# ATSAMC21N18A register map
Registers are 32-bit, access not given, no defined reset value unless marked. A register's access mark holds for its fields unless they carry their own. Addresses are absolute; registers are grouped by the start of their names; [hi:lo] are bit positions; 'fields as' and 'values as' point back to an identical list.

## FUSES
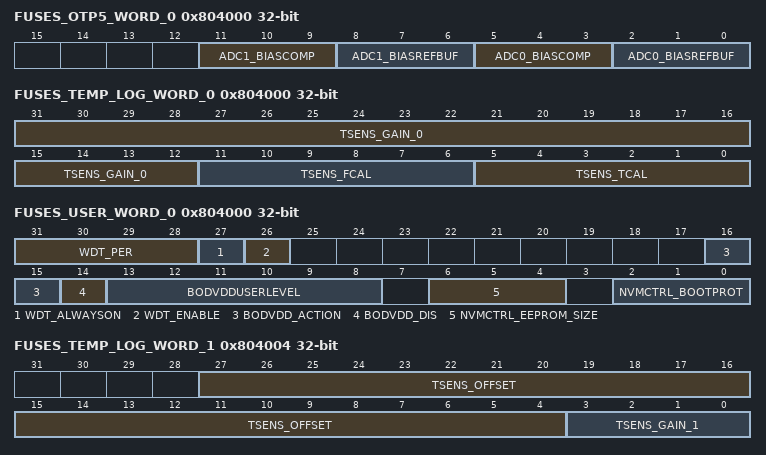
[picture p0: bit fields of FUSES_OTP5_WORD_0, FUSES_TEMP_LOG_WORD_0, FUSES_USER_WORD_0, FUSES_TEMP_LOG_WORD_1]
0x804000 FUSES_OTP5_WORD_0 — OTP5 Page Word 0
  [11:9] ADC1_BIASCOMP, [8:6] ADC1_BIASREFBUF, [5:3] ADC0_BIASCOMP, [2:0] ADC0_BIASREFBUF
0x804000 FUSES_TEMP_LOG_WORD_0 — TEMP_LOG Page Word 0
  [31:12] TSENS_GAIN_0, [11:6] TSENS_FCAL, [5:0] TSENS_TCAL
0x804000 FUSES_USER_WORD_0 — USER Page Word 0
  [31:28] WDT_PER, [27] WDT_ALWAYSON, [26] WDT_ENABLE, [16:15] BODVDD_ACTION, [14] BODVDD_DIS, [13:8] BODVDDUSERLEVEL, [6:4] NVMCTRL_EEPROM_SIZE, [2:0] NVMCTRL_BOOTPROT
0x804004 FUSES_OTP3_WORD_1 — OTP3 Page Word 1
  [31] NVMCTRL_DUMMY2
0x804004 FUSES_TEMP_LOG_WORD_1 — TEMP_LOG Page Word 1
  [27:4] TSENS_OFFSET, [3:0] TSENS_GAIN_1
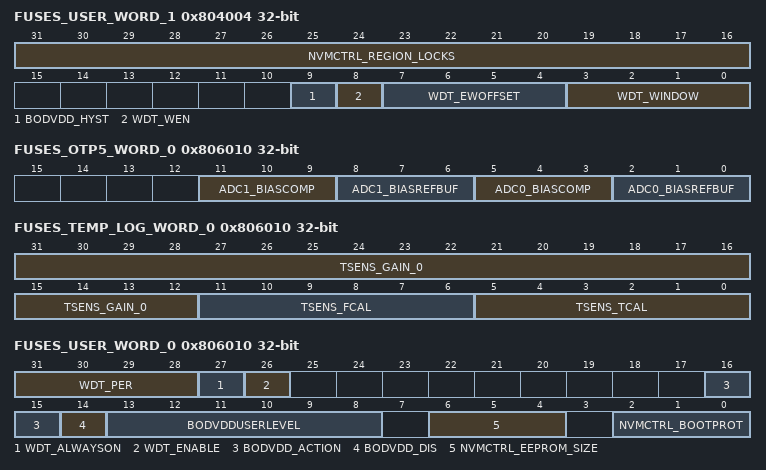
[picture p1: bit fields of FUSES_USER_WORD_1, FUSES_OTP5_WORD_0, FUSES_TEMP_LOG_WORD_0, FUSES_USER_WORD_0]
0x804004 FUSES_USER_WORD_1 — USER Page Word 1
  [31:16] NVMCTRL_REGION_LOCKS, [9] BODVDD_HYST, [8] WDT_WEN, [7:4] WDT_EWOFFSET, [3:0] WDT_WINDOW
0x806010 FUSES_OTP5_WORD_0 — OTP5 Page Word 0
  fields as FUSES_OTP5_WORD_0
0x806010 FUSES_TEMP_LOG_WORD_0 — TEMP_LOG Page Word 0
  [31:12] TSENS_GAIN_0, [11:6] TSENS_FCAL, [5:0] TSENS_TCAL
0x806010 FUSES_USER_WORD_0 — USER Page Word 0
  fields as FUSES_USER_WORD_0
0x806014 FUSES_OTP3_WORD_1 — OTP3 Page Word 1
  [31] NVMCTRL_DUMMY2
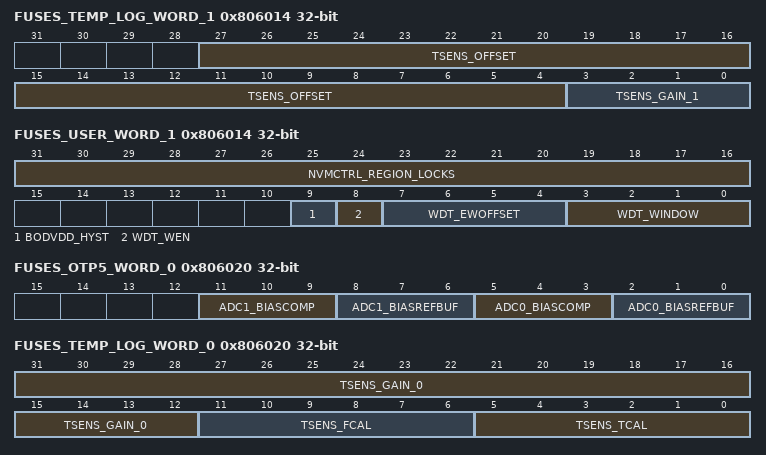
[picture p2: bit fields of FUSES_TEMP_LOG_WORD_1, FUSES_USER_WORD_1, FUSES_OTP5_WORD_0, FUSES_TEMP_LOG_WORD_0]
0x806014 FUSES_TEMP_LOG_WORD_1 — TEMP_LOG Page Word 1
  [27:4] TSENS_OFFSET, [3:0] TSENS_GAIN_1
0x806014 FUSES_USER_WORD_1 — USER Page Word 1
  fields as FUSES_USER_WORD_1
0x806020 FUSES_OTP5_WORD_0 — OTP5 Page Word 0
  fields as FUSES_OTP5_WORD_0
0x806020 FUSES_TEMP_LOG_WORD_0 — TEMP_LOG Page Word 0
  [31:12] TSENS_GAIN_0, [11:6] TSENS_FCAL, [5:0] TSENS_TCAL
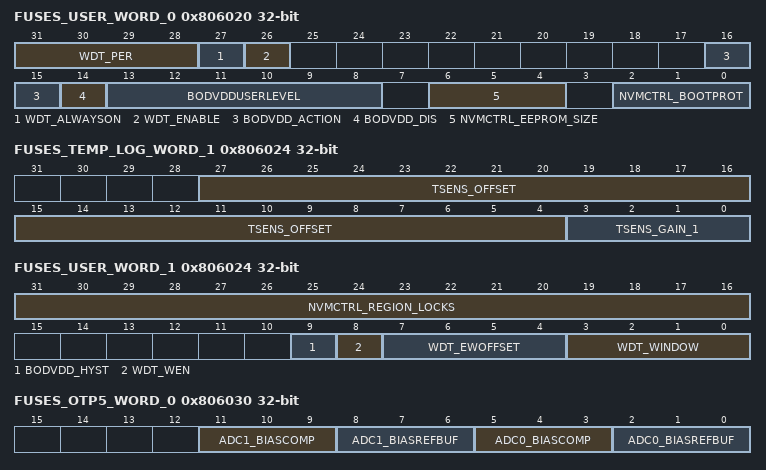
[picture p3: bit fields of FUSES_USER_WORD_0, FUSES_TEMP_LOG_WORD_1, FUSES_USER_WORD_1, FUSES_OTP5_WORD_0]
0x806020 FUSES_USER_WORD_0 — USER Page Word 0
  fields as FUSES_USER_WORD_0
0x806024 FUSES_OTP3_WORD_1 — OTP3 Page Word 1
  [31] NVMCTRL_DUMMY2
0x806024 FUSES_TEMP_LOG_WORD_1 — TEMP_LOG Page Word 1
  [27:4] TSENS_OFFSET, [3:0] TSENS_GAIN_1
0x806024 FUSES_USER_WORD_1 — USER Page Word 1
  fields as FUSES_USER_WORD_1
0x806030 FUSES_OTP5_WORD_0 — OTP5 Page Word 0
  fields as FUSES_OTP5_WORD_0
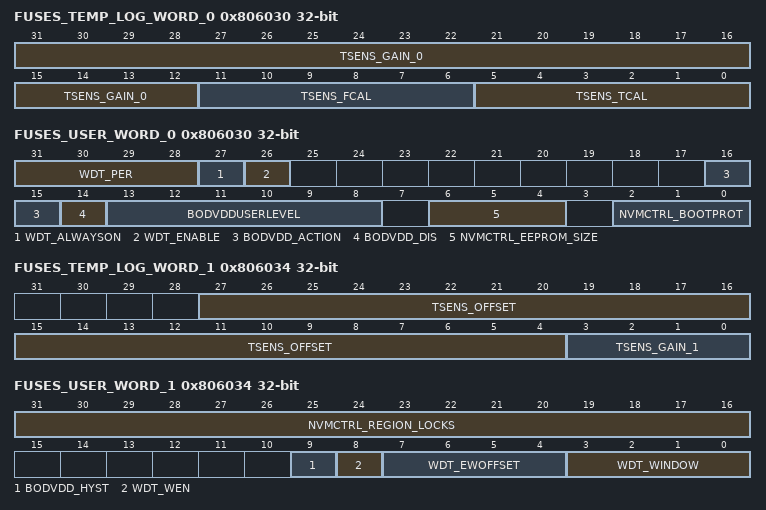
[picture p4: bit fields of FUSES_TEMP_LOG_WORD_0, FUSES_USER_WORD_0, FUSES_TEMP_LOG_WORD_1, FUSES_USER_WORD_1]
0x806030 FUSES_TEMP_LOG_WORD_0 — TEMP_LOG Page Word 0
  [31:12] TSENS_GAIN_0, [11:6] TSENS_FCAL, [5:0] TSENS_TCAL
0x806030 FUSES_USER_WORD_0 — USER Page Word 0
  fields as FUSES_USER_WORD_0
0x806034 FUSES_OTP3_WORD_1 — OTP3 Page Word 1
  [31] NVMCTRL_DUMMY2
0x806034 FUSES_TEMP_LOG_WORD_1 — TEMP_LOG Page Word 1
  [27:4] TSENS_OFFSET, [3:0] TSENS_GAIN_1
0x806034 FUSES_USER_WORD_1 — USER Page Word 1
  fields as FUSES_USER_WORD_1

## OSCCTRL
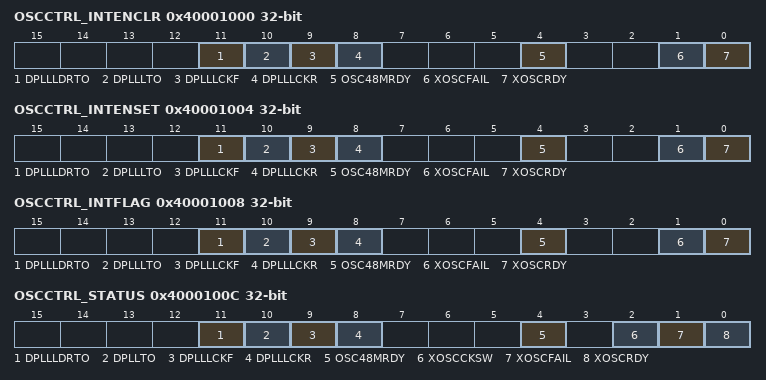
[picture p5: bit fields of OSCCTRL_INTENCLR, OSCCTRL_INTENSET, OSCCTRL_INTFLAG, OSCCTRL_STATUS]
0x40001000 OSCCTRL_INTENCLR — Interrupt Enable Clear
  [11] DPLLLDRTO, [10] DPLLLTO, [9] DPLLLCKF, [8] DPLLLCKR, [4] OSC48MRDY, [1] XOSCFAIL, [0] XOSCRDY
0x40001004 OSCCTRL_INTENSET — Interrupt Enable Set
  fields as OSCCTRL_INTENCLR
0x40001008 OSCCTRL_INTFLAG — Interrupt Flag Status and Clear
  fields as OSCCTRL_INTENCLR
0x4000100C OSCCTRL_STATUS — Power and Clocks Status
  [11] DPLLLDRTO, [10] DPLLTO, [9] DPLLLCKF, [8] DPLLLCKR, [4] OSC48MRDY, [2] XOSCCKSW, [1] XOSCFAIL, [0] XOSCRDY
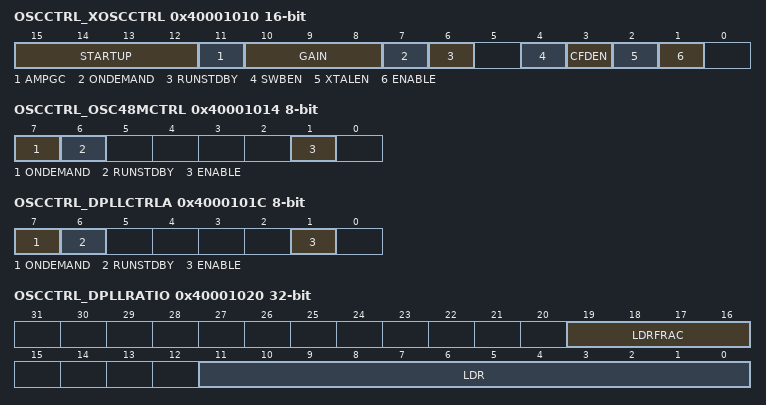
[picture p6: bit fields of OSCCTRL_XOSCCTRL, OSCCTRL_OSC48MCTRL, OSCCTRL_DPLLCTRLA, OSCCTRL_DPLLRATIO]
0x40001010 OSCCTRL_XOSCCTRL 16-bit — External Multipurpose Crystal Oscillator (XOSC) Control
  [15:12] STARTUP, [11] AMPGC, [10:8] GAIN, [7] ONDEMAND, [6] RUNSTDBY, [4] SWBEN, [3] CFDEN, [2] XTALEN, [1] ENABLE
0x40001012 OSCCTRL_CFDPRESC 8-bit — Clock Failure Detector Prescaler
  [2:0] CFDPRESC
0x40001013 OSCCTRL_EVCTRL 8-bit — Event Control
  [0] CFDEO
0x40001014 OSCCTRL_OSC48MCTRL 8-bit — 48MHz Internal Oscillator (OSC48M) Control
  [7] ONDEMAND, [6] RUNSTDBY, [1] ENABLE
0x40001015 OSCCTRL_OSC48MDIV 8-bit — OSC48M Divider
  [3:0] DIV
0x40001016 OSCCTRL_OSC48MSTUP 8-bit — OSC48M Startup Time
  [2:0] STARTUP
0x40001018 OSCCTRL_OSC48MSYNCBUSY — OSC48M Synchronization Busy
  [2] OSC48MDIV
0x4000101C OSCCTRL_DPLLCTRLA 8-bit — DPLL Control
  [7] ONDEMAND, [6] RUNSTDBY, [1] ENABLE
0x40001020 OSCCTRL_DPLLRATIO — DPLL Ratio Control
  [19:16] LDRFRAC, [11:0] LDR
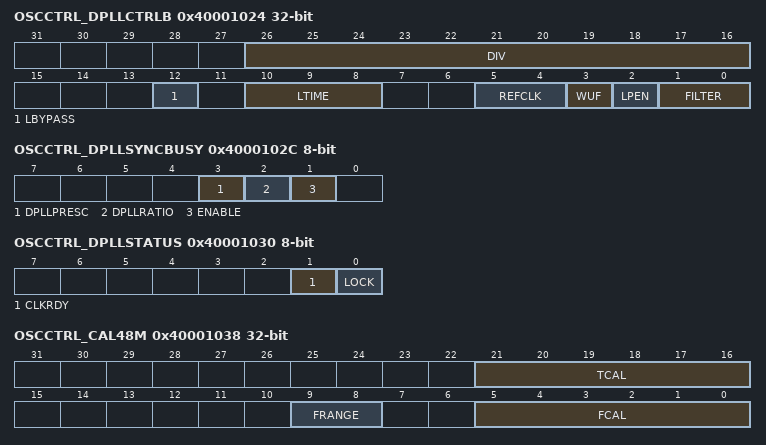
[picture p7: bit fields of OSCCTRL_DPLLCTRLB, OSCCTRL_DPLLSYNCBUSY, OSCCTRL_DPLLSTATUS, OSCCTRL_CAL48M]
0x40001024 OSCCTRL_DPLLCTRLB — Digital Core Configuration
  [26:16] DIV, [12] LBYPASS, [10:8] LTIME, [5:4] REFCLK, [3] WUF, [2] LPEN, [1:0] FILTER
0x40001028 OSCCTRL_DPLLPRESC 8-bit — DPLL Prescaler
  [1:0] PRESC
0x4000102C OSCCTRL_DPLLSYNCBUSY 8-bit — DPLL Synchronization Busy
  [3] DPLLPRESC, [2] DPLLRATIO, [1] ENABLE
0x40001030 OSCCTRL_DPLLSTATUS 8-bit — DPLL Status
  [1] CLKRDY, [0] LOCK
0x40001038 OSCCTRL_CAL48M — 48MHz Oscillator Calibration
  [21:16] TCAL, [9:8] FRANGE, [5:0] FCAL
